# STM32C091 register map
File version: 1.1
CPU: CM0+ r0p0, little endian, MPU, no FPU, 4 interrupt priority bits
Registers are 32-bit, read-write, reset 0x0 unless marked. A register's access mark holds for its fields unless they carry their own. Offsets are from the block's base; [hi:lo] are bit positions; {n}, {i} and the like mark numbered series.

## DBG — DBG address block description
Base 0x40015800
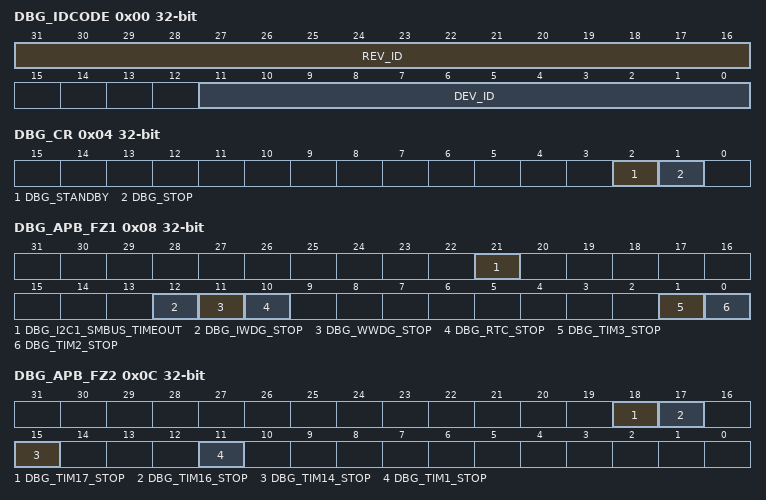
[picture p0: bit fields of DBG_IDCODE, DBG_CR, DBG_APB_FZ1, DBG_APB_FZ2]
0x00 DBG_IDCODE ro reset not defined — DBG device ID code register
  [31:16] REV_ID — Revision identifier This field indicates the revision of the device. Refer to Table 152.
  [11:0] DEV_ID — Device identifier This field indicates the device ID. Refer to Table 152.
0x04 DBG_CR — DBG configuration register
  [2] DBG_STANDBY — Debug Standby and Shutdown modes Debug options in Standby or Shutdown mode.
    0=Digital part powered. From software point of view, exiting Standby and Shutdown modes is identical as fetching reset vector (except for status bits indicating that the MCU exits Standby); 1=Digital part powered and FCLK and HCLK running, derived from the internal RC oscillator remaining active. The MCU generates a system reset so that exiting Standby and Shutdown has the same effect as starting from reset.
  [1] DBG_STOP — Debug Stop mode Debug options in Stop mode. Upon Stop mode exit, the software must re-establish the desired clock configuration.
    0=All clocks disabled, including FCLK and HCLK. Upon Stop mode exit, the CPU is clocked by the HSI internal RC oscillator.; 1=FCLK and HCLK running, derived from the internal RC oscillator remaining active. If Systick is enabled, it may generate periodic interrupt and wake up events.
0x08 DBG_APB_FZ1 — DBG APB freeze register 1
  [21] DBG_I2C1_SMBUS_TIMEOUT — SMBUS timeout when core is halted
    0=Same behavior as in normal mode; 1=The SMBUS timeout is frozen
  [12] DBG_IWDG_STOP — Clocking of IWDG counter when the core is halted This bit enables/disables the clock to the counter of IWDG when the core is halted:
    0=Enable; 1=Disable
  [11] DBG_WWDG_STOP — Clocking of WWDG counter when the core is halted This bit enables/disables the clock to the counter of WWDG when the core is halted:
    0=Enable; 1=Disable
  [10] DBG_RTC_STOP — Clocking of RTC counter when the core is halted This bit enables/disables the clock to the counter of RTC when the core is halted:
    0=Enable; 1=Disable
  [1] DBG_TIM3_STOP — Clocking of TIM3 counter when the core is halted This bit enables/disables the clock to the counter of TIM3 when the core is halted:
    0=Enable; 1=Disable
  [0] DBG_TIM2_STOP — Clocking of TIM2 counter when the core is halted This bit enables/disables the clock to the counter of TIM2 when the core is halted: This bit is only available on STM32C071xx. On the other devices, it is reserved.
    0=Enable; 1=Disable
0x0C DBG_APB_FZ2 — DBG APB freeze register 2
  [all] fields
    0=Enable; 1=Disable
  [18] DBG_TIM17_STOP — Clocking of TIM17 counter when the core is halted This bit enables/disables the clock to the counter of TIM17 when the core is halted:
  [17] DBG_TIM16_STOP — Clocking of TIM16 counter when the core is halted This bit enables/disables the clock to the counter of TIM16 when the core is halted:
  [15] DBG_TIM14_STOP — Clocking of TIM14 counter when the core is halted This bit enables/disables the clock to the counter of TIM14 when the core is halted:
  [11] DBG_TIM1_STOP — Clocking of TIM1 counter when the core is halted This bit enables/disables the clock to the counter of TIM1 when the core is halted:

## DMAMUX — DMAMUX address block description
Base 0x40020800
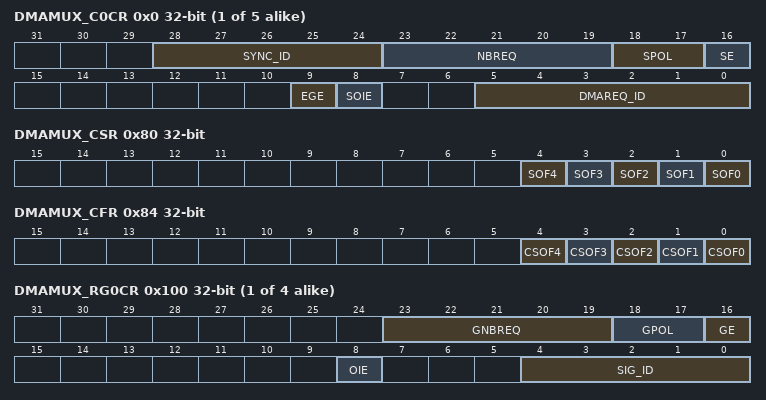
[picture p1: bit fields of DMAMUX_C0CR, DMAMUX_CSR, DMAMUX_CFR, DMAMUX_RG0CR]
{0x0+4i} DMAMUX_C{i}CR (i=0..4) — DMAMUX request line multiplexer channel {i} configuration register
  [28:24] SYNC_ID — Synchronization identification Selects the synchronization input (see Table 44: DMAMUX: assignment of synchronization inputs to resources).
  [23:19] NBREQ — Number of DMA requests minus 1 to forward Defines the number of DMA requests to forward to the DMA controller after a synchronization event, and/or the number of DMA requests before an output event is generated. This field must only be written when both SE and EGE bits are low.
  [18:17] SPOL — Synchronization polarity Defines the edge polarity of the selected synchronization input:
    0=No event (no synchronization, no detection); 1=Rising edge; 2=Falling edge; 3=Rising and falling edges
  [16] SE — Synchronization enable
    0=Synchronization disabled; 1=Synchronization enabled
  [9] EGE — Event generation enable
    0=Event generation disabled; 1=Event generation enabled
  [8] SOIE — Synchronization overrun interrupt enable
    0=Interrupt disabled; 1=Interrupt enabled
  [5:0] DMAREQ_ID — DMA request identification Selects the input DMA request. See the DMAMUX table about assignments of multiplexer inputs to resources.
0x80 DMAMUX_CSR ro — DMAMUX request line multiplexer interrupt channel status register
  [n] SOF{n} (n=0..4) — Synchronization overrun event flag The flag is set when a synchronization event occurs on a DMA request line multiplexer channel x, while the DMA request counter value is lower than NBREQ. The flag is cleared by writing 1 to the corresponding CSOFx bit in DMAMUX_CFR register.
0x84 DMAMUX_CFR wo — DMAMUX request line multiplexer interrupt clear flag register
  [n] CSOF{n} (n=0..4) — Clear synchronization overrun event flag Writing 1 in each bit clears the corresponding overrun flag SOFx in the DMAMUX_CSR register.
{0x100+4i} DMAMUX_RG{i}CR (i=0..3) — DMAMUX request generator channel {i} configuration register
  [23:19] GNBREQ — Number of DMA requests to be generated (minus 1) Defines the number of DMA requests to be generated after a trigger event. The actual number of generated DMA requests is GNBREQ +1. Note: This field must be written only when GE bit is disabled.
  [18:17] GPOL — DMA request generator trigger polarity Defines the edge polarity of the selected trigger input
    0=No event, i.e. no trigger detection nor generation.; 1=Rising edge; 2=Falling edge; 3=Rising and falling edges
  [16] GE — DMA request generator channel x enable
    0=DMA request generator channel x disabled; 1=DMA request generator channel x enabled
  [8] OIE — Trigger overrun interrupt enable
    0=Interrupt on a trigger overrun event occurrence is disabled; 1=Interrupt on a trigger overrun event occurrence is enabled
  [4:0] SIG_ID — Signal identification Selects the DMA request trigger input used for the channel x of the DMA request generator
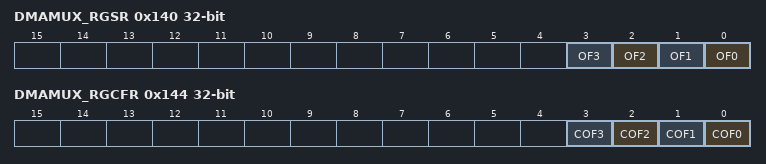
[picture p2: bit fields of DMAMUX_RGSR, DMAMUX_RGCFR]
0x140 DMAMUX_RGSR ro — DMAMUX request generator interrupt status register
  [n] OF{n} (n=0..3) — Trigger overrun event flag The flag is set when a new trigger event occurs on DMA request generator channel x, before the request counter underrun (the internal request counter programmed via the GNBREQ field of the DMAMUX_RGxCR register). The flag is cleared by writing 1 to the corresponding COFx bit in the DMAMUX_RGCFR register.
0x144 DMAMUX_RGCFR wo — DMAMUX request generator interrupt clear flag register
  [n] COF{n} (n=0..3) — Clear trigger overrun event flag Writing 1 in each bit clears the corresponding overrun flag OFx in the DMAMUX_RGSR register.

## WWDG — WWDG address block description
Base 0x40002C00
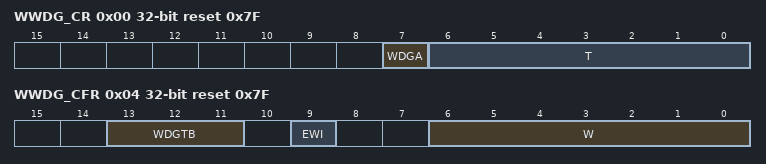
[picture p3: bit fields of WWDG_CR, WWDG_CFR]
0x00 WWDG_CR reset 0x7F — WWDG control register
  [7] WDGA — Activation bit This bit is set by software and only cleared by hardware after a reset. When WDGA = 1, the watchdog can generate a reset.
    0=Watchdog disabled; 1=Watchdog enabled
  [6:0] T — 7-bit counter (MSB to LSB) These bits contain the value of the watchdog counter, decremented every (4096 x 2<sup>WDGTB[2:0]</sup>) PCLK cycles. A reset is produced when it is decremented from 0x40 to 0x3F (T6 becomes cleared).
0x04 WWDG_CFR reset 0x7F — WWDG configuration register
  [13:11] WDGTB — Timer base The timebase of the prescaler can be modified as follows:
    0=CK counter clock (PCLK div 4096) div 1; 1=CK counter clock (PCLK div 4096) div 2; 2=CK counter clock (PCLK div 4096) div 4; 3=CK counter clock (PCLK div 4096) div 8; 4=CK counter clock (PCLK div 4096) div 16; 5=CK counter clock (PCLK div 4096) div 32; 6=CK counter clock (PCLK div 4096) div 64; 7=CK counter clock (PCLK div 4096) div 128
  [9] EWI — Early wake-up interrupt enable Set by software and cleared by hardware after a reset. When set, an interrupt occurs whenever the counter reaches the value 0x40.
  [6:0] W — 7-bit window value These bits contain the window value to be compared with the down-counter.
0x08 WWDG_SR — WWDG status register
  [0] EWIF — Early wake-up interrupt flag This bit is set by hardware when the counter has reached the value 0x40. It must be cleared by software by writing 0. Writing 1 has no effect. This bit is also set if the interrupt is not enabled.

## Notices in the file
Copyright (c) 2024 STMicroelectronics.
SPDX-License-Identifier: Apache-2.0
Licensed under the Apache License, Version 2.0 (the "License");
you may not use this file except in compliance with the License.
You may obtain a copy of the License at
http://www.apache.org/licenses/LICENSE-2.0
Unless required by applicable law or agreed to in writing, software
distributed under the License is distributed on an "AS IS" BASIS,
WITHOUT WARRANTIES OR CONDITIONS OF ANY KIND, either express or implied.
See the License for the specific language governing permissions and
limitations under the License.
